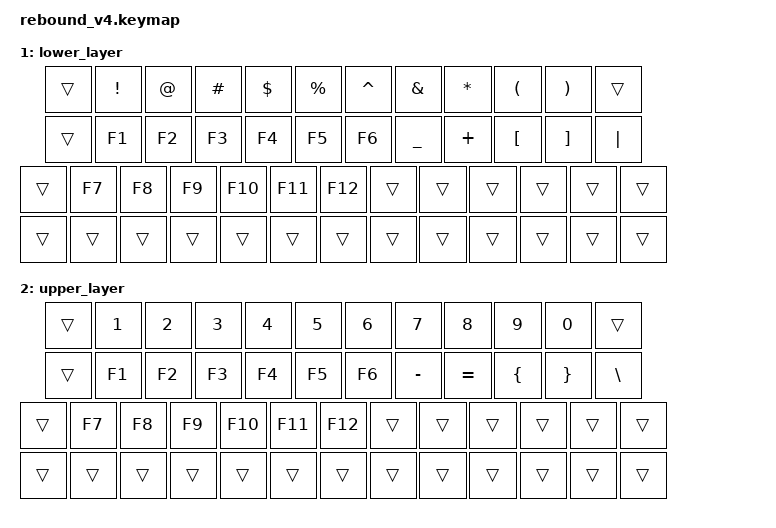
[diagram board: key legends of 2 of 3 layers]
/*
 * Copyright (c) 2020 The ZMK Contributors
 *
 * SPDX-License-Identifier: MIT
 */

#include <behaviors.dtsi>
#include <dt-bindings/zmk/keys.h>
#include <dt-bindings/zmk/bt.h>
#include <dt-bindings/zmk/modifiers.h>
#include <dt-bindings/zmk/outputs.h>

/ {
    behaviors {
        hm: homerow_mods {
            compatible = "zmk,behavior-hold-tap";
            label = "HOMEROW_MODS";
            #binding-cells = <2>;
            tapping_term_ms = <175>;
            flavor = "tap-preferred";
            bindings = <&kp>, <&kp>;
        };
    };

    keymap {
        compatible = "zmk,keymap";
        
        default_layer {
// ----------------------------------------------------------------------------------------------------------------
// |  ESC  |   Q   |   W   |   E    |  R  |   T  |                |  Y  |    U   |   I   |   O   |   P   |  BSPC |
// |  TAB  |   A   |   S   |   D    |  F  |   G  |    |      |    |  H  |    J   |   K   |   L   |   '   |   '   |
// | SHIFT |   Z   |   X   |   C    |  V  |   B  |    |      |    |  N  |    M   |   ,   |   .   |   /   | RETURN|
// | CTRL  |  ALT  |  GUI  |  NUM   | LWR |  SPC |    |      |    | SPC |  RAISE | LEFT  |  DOWN |  UP   | RIGHT |
// ----------------------------------------------------------------------------------------------------------------
		bindings = <
&kp TAB &kp Q &kp W &kp E &kp R &kp T &kp Y &kp U &kp I &kp O &kp P &kp BSPC
&kp ESC &kp A &kp S &kp D &kp F &kp G &none &kp H &kp J &kp K &kp L &kp SEMI &kp APOS
&kp LEFT_SHIFT &kp Z &kp X &kp C &kp V &kp B &none &kp N &kp M &kp COMMA &kp PERIOD &kp FSLH &kp RETURN
&kp LEFT_CONTROL &kp LEFT_ALT &kp LEFT_GUI &none &none &kp SPACE &none &kp SPACE &none &kp LEFT_ARROW &kp DOWN_ARROW &kp UP_ARROW &kp RIGHT_ARROW
                        >;

			sensor-bindings = <&inc_dec_kp DEL BSPC>;
                };

        lower_layer {
// -----------------------------------------------------------------------------------------
// |     |  !  |  @  |  #  |  $  |  %  |                |  ^  |  &  |  *  | '(' | ')' |     |
// |     |  F1 |  F2 |  F3 |  F4 |  F5 |    |      |    |  F6 |  _  |  +  |  {  |  }  | '|' |
// |     |  F7 |  F8 |  F9 | F10 | F11 |    |      |    | F12 |     |     |     |     |     |
// |     |     |     |     |     |     |    |      |    |     |     |     |     |     |     |
// -----------------------------------------------------------------------------------------
		bindings = <
&trans &kp EXCL &kp AT &kp HASH &kp DOLLAR &kp PERCENT &kp CARET &kp AMPERSAND &kp STAR &kp LPAR &kp RPAR &trans
&trans &kp F1 &kp F2 &kp F3 &kp F4 &kp F5 &kp F6 &kp UNDERSCORE &kp PLUS &kp LEFT_BRACKET &kp RIGHT_BRACKET &kp PIPE
&trans &kp F7 &kp F8 &kp F9 &kp F10 &kp F11 &kp F12 &trans &trans &trans &trans &trans &trans
&trans &trans &trans &trans &trans &trans &trans &trans &trans &trans &trans &trans &trans 
                        >;

			sensor-bindings = <&inc_dec_kp DEL BSPC>;
                };

        upper_layer {
// -----------------------------------------------------------------------------------------
// |     |  1  |  2  |  3  |  4  |  5  |                |  6  |  7  |  8  |  9  |  0  |     |
// |     |  F1 |  F2 |  F3 |  F4 |  F5 |    |      |    |  F6 |  -  |  =  |  [  |  ]  |  \  |
// |     |  F7 |  F8 |  F9 | F10 | F11 |    |      |    | F12 |     |     |     |     |     |
// |     |     |     |     |     |     |    |      |    |     |     |     |     |     |     |
// -----------------------------------------------------------------------------------------
		bindings = <
&trans &kp N1 &kp N2 &kp N3 &kp N4 &kp N5 &kp N6 &kp N7 &kp N8 &kp N9 &kp N0 &trans
&trans &kp F1 &kp F2 &kp F3 &kp F4 &kp F5 &kp F6 &kp MINUS &kp EQUAL &kp LEFT_BRACE &kp RIGHT_BRACE &kp BSLH
&trans &kp F7 &kp F8 &kp F9 &kp F10 &kp F11 &kp F12 &trans &trans &trans &trans &trans &trans
&trans &trans &trans &trans &trans &trans &trans &trans &trans &trans &trans &trans &trans 
                        >;

			sensor-bindings = <&inc_dec_kp DEL BSPC>;
                };

	};
};
